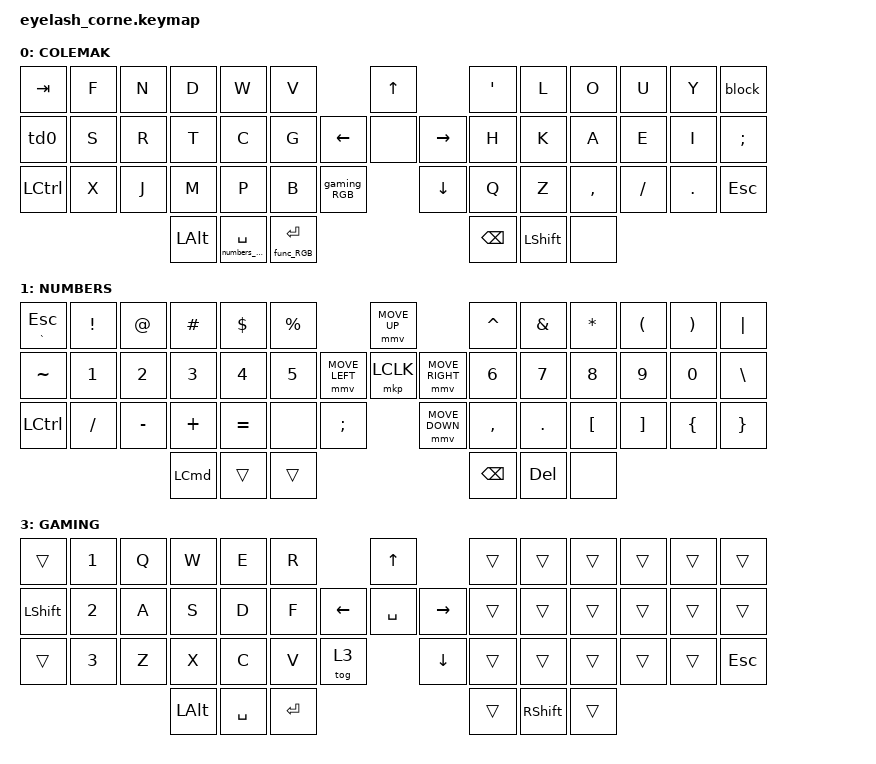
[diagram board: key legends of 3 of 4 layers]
#define ZMK_POINTING_DEFAULT_MOVE_VAL 1800  // 600
#define ZMK_POINTING_DEFAULT_SCRL_VAL 25   // 10

#include <input/processors.dtsi>
#include <zephyr/dt-bindings/input/input-event-codes.h>
#include <behaviors.dtsi>
#include <dt-bindings/zmk/bt.h>
#include <dt-bindings/zmk/keys.h>
#include <dt-bindings/zmk/outputs.h>
#include <dt-bindings/zmk/pointing.h>
#include <dt-bindings/zmk/rgb.h>
#include "keys_pl.h"

&mmv_input_listener { input-processors = <&zip_xy_scaler 2 1>; };

&msc_input_listener { input-processors = <&zip_scroll_scaler 2 1>; };

&msc {
    acceleration-exponent = <1>;      // 0
    time-to-max-speed-ms = <100>;       // 300
    delay-ms = <0>;                   // 0
};

&mmv {
    time-to-max-speed-ms = <500>;
    acceleration-exponent = <1>;
    trigger-period-ms = <16>;
};

&lt { tapping-term-ms = <140>; };

/ {
    behaviors {
        td0: td0 {
            compatible = "zmk,behavior-tap-dance";
            display-name = "Shift/Caps Lock Tap Dance";
            #binding-cells = <0>;
            bindings = <&sk LEFT_SHIFT>, <&kp CAPS>;

            label = "Shift + Caps";
        };

        ht_numbers_rgb: ht_numbers_rgb {
            compatible = "zmk,behavior-hold-tap";
            label = "HT_NUMBERS_RGB";
            bindings = <&numbers_RGB>, <&kp>;

            #binding-cells = <2>;
            tapping-term-ms = <140>;
            flavor = "tap-preferred";
        };

        ht_func_rgb: ht_func_rgb {
            compatible = "zmk,behavior-hold-tap";
            label = "HT_FUNC_RGB";
            bindings = <&func_RGB>, <&kp>;

            #binding-cells = <2>;
            tapping-term-ms = <140>;
            flavor = "tap-preferred";
        };

        td_semi: td_semi {
            compatible = "zmk,behavior-tap-dance";
            display-name = "Shift/Caps Lock Tap Dance";
            #binding-cells = <0>;
            bindings = <&sk COMMA>, <&kp SEMI>;

            label = "TD_SEMI";
        };

        htd_semi: htd_semi {
            compatible = "zmk,behavior-hold-tap";
            label = "HTD_SEMI";
            bindings = <&kp>, <&td_semi>;

            #binding-cells = <2>;
            tapping-term-ms = <140>;
            flavor = "tap-preferred";
        };
    };

    rgb_encoder: rgb_encoder {
        compatible = "zmk,behavior-sensor-rotate";
        #sensor-binding-cells = <0>;
        bindings = <&rgb_ug RGB_BRI>, <&rgb_ug RGB_BRD>;
    };

    scroll_encoder: scroll_encoder {
        compatible = "zmk,behavior-sensor-rotate";
        #sensor-binding-cells = <0>;
        bindings = <&msc SCRL_DOWN>, <&msc SCRL_UP>;

        tap-ms = <100>;
    };

    combos {
        compatible = "zmk,combos";

        Zs {
            timeout-ms = <200>;
            bindings = <&kp PL_Z>;
            key-positions = <47 37>;
            layers = <0>;
        };

        Xs {
            timeout-ms = <200>;
            bindings = <&kp PL_X>;
            key-positions = <47 29>;
            layers = <0>;
        };

        Cs {
            timeout-ms = <200>;
            bindings = <&kp PL_C>;
            key-positions = <47 17>;
            layers = <0>;
        };

        Ns {
            timeout-ms = <200>;
            bindings = <&kp PL_N>;
            key-positions = <47 2>;
            layers = <0>;
        };

        Ls {
            timeout-ms = <200>;
            bindings = <&kp PL_L>;
            key-positions = <8 47>;
            layers = <0>;
        };

        Es {
            timeout-ms = <200>;
            bindings = <&kp PL_E>;
            key-positions = <47 25>;
            layers = <0>;
        };

        Os {
            timeout-ms = <200>;
            bindings = <&kp PL_O>;
            key-positions = <47 9>;
            layers = <0>;
        };

        As {
            timeout-ms = <200>;
            bindings = <&kp PL_A>;
            key-positions = <47 24>;
            layers = <0>;
        };

        Ss {
            timeout-ms = <200>;
            bindings = <&kp PL_S>;
            key-positions = <47 14>;
            layers = <0>;
        };
    };

    macros {
        numbers_RGB: numbers_RGB {
            compatible = "zmk,behavior-macro";
            #binding-cells = <0>;
            bindings =
                <&macro_press>,
                <&mo 1>,
                <&macro_tap>,
                <&rgb_ug RGB_COLOR_HSB(235,70,50)>,
                <&macro_pause_for_release>,
                <&macro_release>,
                <&mo 1>,
                <&macro_tap>,
                <&rgb_ug RGB_COLOR_HSB(200,70,60)>;
        };

        func_RGB: func_RGB {
            compatible = "zmk,behavior-macro";
            #binding-cells = <0>;
            bindings =
                <&macro_press>,
                <&mo 2>,
                <&macro_tap>,
                <&rgb_ug RGB_COLOR_HSB(125,70,75)>,
                <&macro_pause_for_release>,
                <&macro_release>,
                <&mo 2>,
                <&macro_tap>,
                <&rgb_ug RGB_COLOR_HSB(200,70,60)>;
        };

        gaming_RGB: gaming_RGB {
            compatible = "zmk,behavior-macro";
            #binding-cells = <0>;
            bindings =
                <&macro_press>,
                <&tog 3>,
                <&macro_tap>,
                <&rgb_ug RGB_COLOR_HSB(0,100,50)>;
        };

        xlookup: xlookup {
            compatible = "zmk,behavior-macro";
            #binding-cells = <0>;
            bindings = <&kp EQUAL &kp X &kp L &kp O &kp O &kp K &kp U &kp P &kp LPAR>;
            label = "XLOOKUP";
        };

        sumifs: sumifs {
            compatible = "zmk,behavior-macro";
            #binding-cells = <0>;
            bindings = <&kp EQUAL &kp S &kp U &kp M &kp I &kp F &kp S &kp LPAR>;
            label = "SUMIFS";
        };

        left: left {
            compatible = "zmk,behavior-macro";
            #binding-cells = <0>;
            bindings = <&kp EQUAL &kp L &kp E &kp F &kp T &kp LPAR>;
            label = "LEFT";
        };

        mid: mid {
            compatible = "zmk,behavior-macro";
            #binding-cells = <0>;
            bindings = <&kp EQUAL &kp M &kp I &kp D &kp LPAR>;
            label = "MID";
        };

        copy: copy {
            compatible = "zmk,behavior-macro";
            #binding-cells = <0>;
            bindings = <&sk LCTRL &kp C>;
            label = "COPY";
        };

        paste: paste {
            compatible = "zmk,behavior-macro";
            #binding-cells = <0>;
            bindings = <&sk LCTRL &kp V>;
            label = "PASTE";
        };

        countif: countif {
            compatible = "zmk,behavior-macro";
            #binding-cells = <0>;
            bindings = <&kp EQUAL &kp C &kp O &kp U &kp N &kp T &kp I &kp F &kp S &kp LPAR>;
            label = "COUNTIF";
        };

        block: block {
            compatible = "zmk,behavior-macro";
            #binding-cells = <0>;
            wait-ms = <100>;
            tap-ms = <50>;
            bindings =
                <&macro_press>,
                <&kp LCTRL &kp LALT>,
                <&macro_tap>,
                <&kp DEL>,
                <&macro_release>,
                <&kp LCTRL &kp LALT>,
                <&macro_wait_time 1000>,
                <&macro_tap>,
                <&kp TAB>,
                <&macro_wait_time 100>,
                <&macro_tap>,
                <&kp UP &kp ENTER>;

            label = "BLOCK";
        };
    };

    keymap {
        compatible = "zmk,keymap";

        default_layer {
            display-name = "COLEMAK";
            bindings = <
&kp TAB    &kp F  &kp N  &kp D         &kp W                    &kp V                                          &kp UP               &kp SQT        &kp L           &kp O      &kp U     &kp Y    &block
&td0       &kp S  &kp R  &kp T         &kp C                    &kp G                                &kp LEFT  &none     &kp RIGHT  &kp H          &kp K           &kp A      &kp E     &kp I    &kp SEMI
&kp LCTRL  &kp X  &kp J  &kp M         &kp P                    &kp B                 &gaming_RGB              &kp DOWN             &kp Q          &kp Z           &kp COMMA  &kp FSLH  &kp DOT  &kp ESC
                         &kp LEFT_ALT  &ht_numbers_rgb 0 SPACE  &ht_func_rgb 0 ENTER                                                &kp BACKSPACE  &kp LEFT_SHIFT  &none
            >;

            sensor-bindings = <&inc_dec_kp LC(PAGE_DOWN) LC(PAGE_UP)>;
        };

        lower_layer {
            display-name = "NUMBERS";
            bindings = <
&mt GRAVE ESCAPE  &kp EXCL   &kp AT     &kp HASH          &kp DOLLAR  &kp PERCENT                              &mmv MOVE_UP                     &kp CARET      &kp AMPS    &kp ASTERISK      &kp LEFT_PARENTHESIS  &kp RIGHT_PARENTHESIS  &kp PIPE
&kp TILDE         &kp N1     &kp N2     &kp N3            &kp N4      &kp N5                   &mmv MOVE_LEFT  &mkp LCLK       &mmv MOVE_RIGHT  &kp N6         &kp N7      &kp N8            &kp N9                &kp N0                 &kp BSLH
&kp LEFT_CONTROL  &kp SLASH  &kp MINUS  &kp PLUS          &kp EQUAL   &none        &kp SEMI                    &mmv MOVE_DOWN                   &kp COMMA      &kp DOT     &kp LEFT_BRACKET  &kp RIGHT_BRACKET     &kp LEFT_BRACE         &kp RIGHT_BRACE
                                        &kp LEFT_COMMAND  &trans      &trans                                                                    &kp BACKSPACE  &kp DELETE  &none
            >;

            sensor-bindings = <&inc_dec_kp C_VOLUME_UP C_VOLUME_DOWN>;
        };

        raise_layer {
            display-name = "FCONFIG";
            bindings = <
&kp LEFT_ALT      &kp HOME  &none     &kp UP        &none         &kp PAGE_UP                             &kp K_SCROLL_UP           &none         &kp F1        &kp F2   &kp F3   &kp F4   &kp SCROLLLOCK
&kp LEFT_SHIFT    &kp END   &kp LEFT  &kp DOWN      &kp RIGHT     &kp PAGE_DOWN                    &none  &mkp LCLK          &none  &none         &kp F5        &kp F6   &kp F7   &kp F8   &kp PAUSE_BREAK
&sk LEFT_CONTROL  &mid      &xlookup  &sumifs       &countif      &kp LS(LG(S))  &bt BT_CLR_ALL           &kp K_SCROLL_DOWN         &none         &kp F9        &kp F10  &kp F11  &kp F12  &kp INS
                                      &bt BT_SEL 0  &bt BT_SEL 1  &none                                                             &out OUT_TOG  &bt BT_SEL 2
            >;

            sensor-bindings = <&scroll_encoder>;
        };

        layer_3 {
            display-name = "GAMING";
            bindings = <
&trans          &kp N1  &kp Q  &kp W         &kp E      &kp R                              &kp UP_ARROW                     &trans  &trans           &trans  &trans  &trans  &trans
&kp LEFT_SHIFT  &kp N2  &kp A  &kp S         &kp D      &kp F              &kp LEFT_ARROW  &kp SPACE       &kp RIGHT_ARROW  &trans  &trans           &trans  &trans  &trans  &trans
&trans          &kp N3  &kp Z  &kp X         &kp C      &kp V    &tog 3                    &kp DOWN_ARROW                   &trans  &trans           &trans  &trans  &trans  &kp ESC
                               &kp LEFT_ALT  &kp SPACE  &kp RET                                                             &trans  &kp RIGHT_SHIFT  &trans
            >;

            sensor-bindings = <&inc_dec_kp C_VOLUME_UP C_VOLUME_DOWN>;
        };
    };
};
